VERSION ""

NS_ :

BS_:
BU_:
BO_ 2147484161 MOTOR_TORQUE: 8 Vector__XXX
   SG_ Command : 24|8@1+ (1,0) [0|255] "" Vector__XXX
   SG_ Torque : 32|16@1- (1,0) [-32768|32767] "Nm" Vector__XXX

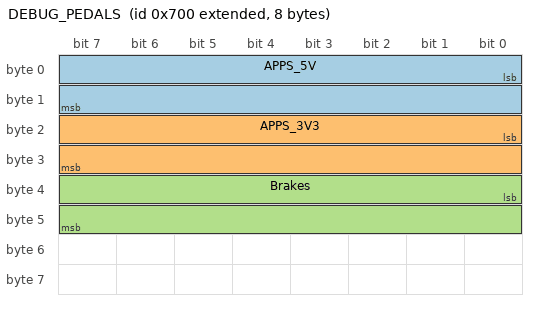
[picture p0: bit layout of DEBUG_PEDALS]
BO_ 2147485440 DEBUG_PEDALS: 8 Vector__XXX
   SG_ APPS_5V : 0|16@1+ (1,0) [0|1023] "ADC" Vector__XXX
   SG_ APPS_3V3 : 16|16@1+ (1,0) [0|1023] "" Vector__XXX
   SG_ Brakes : 32|16@1+ (1,0) [0|1023] "" Vector__XXX

BO_ 2147485441 DEBUG_STATE: 8 Vector__XXX
   SG_ CarState : 0|8@1+ (1,0) [0|3] "" Vector__XXX

BO_ 2147485442 DEBUG_FAULT: 8 Vector__XXX
   SG_ APPS_Diff : 0|16@1+ (1,0) [0|1023] "ADC" Vector__XXX

BA_DEF_ BO_ "GenMsgBackgroundColor" STRING ;
BA_DEF_ BO_ "GenMsgForegroundColor" STRING ;
BA_DEF_ BO_ "filterlabeling" INT 0 0;
BA_ "GenMsgForegroundColor" BO_ 2147484161 "#ffffff";
BA_ "GenMsgBackgroundColor" BO_ 2147484161 "#a1352c";
BA_ "GenMsgForegroundColor" BO_ 2147485440 "#ffffff";
BA_ "GenMsgBackgroundColor" BO_ 2147485440 "#9142ff";
BA_ "GenMsgBackgroundColor" BO_ 2147485441 "#04c304";
BA_ "GenMsgBackgroundColor" BO_ 2147485442 "#caca06";
BA_DEF_DEF_ "GenMsgBackgroundColor" "#ffffff";
BA_DEF_DEF_ "GenMsgForegroundColor" "#000000";
BA_DEF_DEF_ "filterlabeling" 1;
